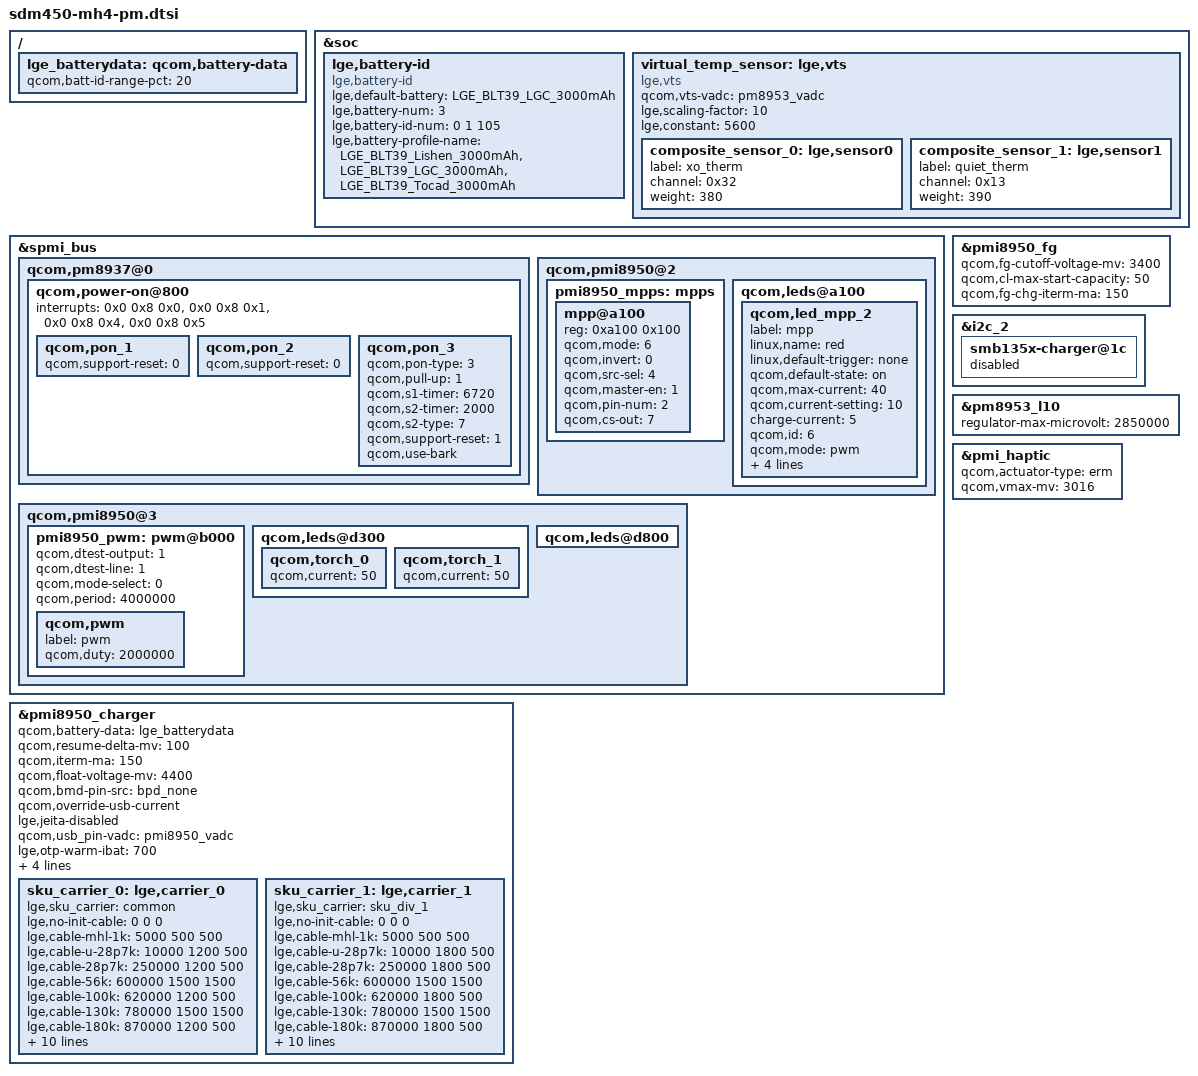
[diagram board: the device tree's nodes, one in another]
/*
 * Copyright (c) 2017, The Linux Foundation. All rights reserved.
 *
 * This program is free software; you can redistribute it and/or modify
 * it under the terms of the GNU General Public License version 2 and
 * only version 2 as published by the Free Software Foundation.
 *
 * This program is distributed in the hope that it will be useful,
 * but WITHOUT ANY WARRANTY; without even the implied warranty of
 * MERCHANTABILITY or FITNESS FOR A PARTICULAR PURPOSE.  See the
 * GNU General Public License for more details.
 */

/{
	lge_batterydata: qcom,battery-data {
		qcom,batt-id-range-pct = <20>;
		#include "../battery_profile/LGE_BLT39_Lishen_3000mAh.dtsi"
		#include "../battery_profile/LGE_BLT39_LGC_3000mAh.dtsi"
		#include "../battery_profile/LGE_BLT39_Tocad_3000mAh.dtsi"
	};
};

&soc {
	lge,battery-id{
		compatible = "lge,battery-id";
		/delete-property/ lge,restrict-mode-enabled;
		/*default battery profile*/
		lge,default-battery = "LGE_BLT39_LGC_3000mAh";
		/*Total number of combined of battery cell and battery id */
		lge,battery-num = <3>;
		/* battery id and battery profile match numbers */
		lge,battery-id-num = <0 1 105>;
		/* battery profile */
		lge,battery-profile-name = "LGE_BLT39_Lishen_3000mAh",
						"LGE_BLT39_LGC_3000mAh",
						"LGE_BLT39_Tocad_3000mAh";
	};

	/* vts = (0.38*xo_therm) + (0.39*quiet_therm) + (5.6) */
	virtual_temp_sensor: lge,vts {
		compatible = "lge,vts";
		qcom,vts-vadc = <&pm8953_vadc>;
		lge,scaling-factor= <10>;
		lge,constant = <5600>;
		composite_sensor_0: lge,sensor0 {
			label = "xo_therm";
			channel = <0x32>;
			weight = <380>;
		};
		composite_sensor_1: lge,sensor1 {
			label = "quiet_therm";
			channel = <0x13>;
			weight = <390>;
		};
	};
};

&spmi_bus {
	qcom,pm8937@0 {
		qcom,power-on@800 {
			interrupts = <0x0 0x8 0x0>,
				     <0x0 0x8 0x1>,
				     <0x0 0x8 0x4>,
				     <0x0 0x8 0x5>;
			interrupt-names = "kpdpwr", "resin",
				"resin-bark", "kpdpwr-resin-bark";

			qcom,pon_1 {
				status = "ok";
				qcom,support-reset = <0>;
			};
			qcom,pon_2 {
				status = "ok";
				qcom,support-reset = <0>;
			};
			qcom,pon_3 {
				status = "ok";
				qcom,pon-type = <3>;
				qcom,pull-up = <1>;
				qcom,s1-timer = <6720>;
				qcom,s2-timer = <2000>;
				qcom,s2-type = <7>;
				qcom,support-reset = <1>;
				qcom,use-bark;
			};
		};
	};

	qcom,pmi8950@2 {
		pmi8950_mpps: mpps {
			mpp@a100 {
				status = "okay";
				reg = <0xa100 0x100>;
				qcom,mode = <6>;
				qcom,invert = <0>;
				qcom,src-sel = <4>;
				qcom,master-en = <1>;
				qcom,pin-num = <2>;
				qcom,cs-out = <7>;
			};
		};
		qcom,leds@a100 {
			status = "okay";
			qcom,led_mpp_2 {
				label = "mpp";
				linux,name = "red";
				linux,default-trigger = "none";
				qcom,default-state = "on";
				qcom,max-current = <40>;
				qcom,current-setting = <10>;
				charge-current = <5>;
				qcom,id = <6>;
				qcom,mode = "pwm";
				qcom,pwm-us = <1000>;
				qcom,source-sel = <8>;
				qcom,mode-ctrl = <0x60>;
				pwms = <&pmi8950_pwm 0 0>;
			};
		};
	};

	qcom,pmi8950@3 {
		pmi8950_pwm: pwm@b000 {
			status = "ok";
			qcom,dtest-output = <1>;
			qcom,dtest-line = <1>;
			qcom,mode-select = <0>;
			qcom,period = <4000000>;
			qcom,pwm {
				label = "pwm";
				qcom,duty = <2000000>;
			};
		};
		qcom,leds@d300 {
			qcom,torch_0 {
				qcom,current = <50>;
			};
			qcom,torch_1 {
				qcom,current = <50>;
			};
		};
		qcom,leds@d800 {
			/delete-property/ qcom,en-ext-pfet-sc-pro;
		};
	};
};

&pmi8950_fg {
	qcom,fg-cutoff-voltage-mv = <3400>;
	qcom,cl-max-start-capacity = <50>;
	qcom,fg-chg-iterm-ma = <150>;
};

&pmi8950_charger {
	qcom,battery-data = <&lge_batterydata>;
	qcom,resume-delta-mv = <100>;
	qcom,iterm-ma = <150>;
	qcom,float-voltage-mv = <4400>;

	qcom,bmd-pin-src = "bpd_none";
	qcom,override-usb-current;
	lge,jeita-disabled;
        /delete-property/lge,parallel-supported;
	qcom,usb_pin-vadc = <&pmi8950_vadc>;

	lge,otp-warm-ibat = <700>;
	lge,otp-cold-ibat = <700>;
	lge,battery-spec-size = <7>;
		lge,battery-spec = <
			0 10 4000 1800	/* 0.5C */
			0 10 4400 550	/* 0.2C */
			10 20 4000 1800	/* 0.5C */
			10 20 4400 700	/* 0.3C */
			20 45 4200 1800	/* 0.5C */
			20 45 4400 1800	/* 0.5C */
			45 60 4100 1800	/* 0.5C */
		>;

	sku_carrier_0:	lge,carrier_0 {
		lge,sku_carrier = "common";

		/* ref resistance 200K */
		lge,no-init-cable = <0 0 0>;
		lge,cable-mhl-1k = <5000 500 500>;
		lge,cable-u-28p7k = <10000 1200 500>;
		lge,cable-28p7k = <250000 1200 500>;
		lge,cable-56k = <600000 1500 1500>;
		lge,cable-100k = <620000 1200 500>;
		lge,cable-130k = <780000 1500 1500>;
		lge,cable-180k = <870000 1200 500>;
		lge,cable-200k = <910000 1200 500>;
		lge,cable-220k = <960000 1200 500>;
		lge,cable-270k = <1050000 1200 500>;
		lge,cable-330k = <1150000 1200 500>;
		lge,cable-620k = <1380000 1200 500>;
		lge,cable-910k = <1630000 1500 1500>;
		lge,cable-none = <1900000 1200  500>;

		lge,usb-max-current-ma = <1200>;
		lge,fastchg-current-ma = <1200>;

		lge,hvdcp-not-supported;
	};
	sku_carrier_1:	lge,carrier_1 {
		lge,sku_carrier = "sku_div_1";

		/* ref resistance 200K */
		lge,no-init-cable = <0 0 0>;
		lge,cable-mhl-1k = <5000 500 500>;
		lge,cable-u-28p7k = <10000 1800 500>;
		lge,cable-28p7k = <250000 1800 500>;
		lge,cable-56k = <600000 1500 1500>;
		lge,cable-100k = <620000 1800 500>;
		lge,cable-130k = <780000 1500 1500>;
		lge,cable-180k = <870000 1800 500>;
		lge,cable-200k = <910000 1800 500>;
		lge,cable-220k = <960000 1800 500>;
		lge,cable-270k = <1050000 1800 500>;
		lge,cable-330k = <1150000 1800 500>;
		lge,cable-620k = <1380000 1800 500>;
		lge,cable-910k = <1630000 1500 1500>;
		lge,cable-none = <1900000 1800  500>;

		lge,usb-max-current-ma = <1800>;
		lge,fastchg-current-ma = <1800>;

		lge,hvdcp-not-supported;
	};
};

&i2c_2 {
    /* Parallel-charger configuration */
    smb135x-charger@1c{
        status = "disabled";
    };
};

&pm8953_l10 {
        regulator-max-microvolt = <2850000>;
};

&pmi_haptic{
	status = "okay";
	qcom,actuator-type = "erm";
	qcom,vmax-mv = <3016>;
};


